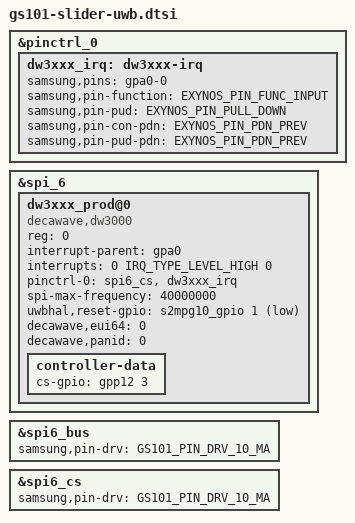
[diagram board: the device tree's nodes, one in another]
// SPDX-License-Identifier: GPL-2.0
/*
 * Google GS101 Board device tree source
 *
 * Copyright (c) 2021 Google, LLC
 *		https://www.google.com
*/

#include <dt-bindings/gpio/gpio.h>
#include <dt-bindings/pinctrl/samsung.h>

&pinctrl_0 {
	dw3xxx_irq: dw3xxx-irq {
		samsung,pins = "gpa0-0";
		samsung,pin-function = <EXYNOS_PIN_FUNC_INPUT>;
		samsung,pin-pud = <EXYNOS_PIN_PULL_DOWN>;
		samsung,pin-con-pdn = <EXYNOS_PIN_PDN_PREV>;
		samsung,pin-pud-pdn = <EXYNOS_PIN_PDN_PREV>;
	};
};

&spi_6 {
	status = "okay";
	dw3xxx_prod@0 {
		compatible = "decawave,dw3000";
		reg = <0>;

		interrupt-parent = <&gpa0>;
		interrupts = <0 IRQ_TYPE_LEVEL_HIGH 0>;

		pinctrl-names = "default";
		pinctrl-0 = <&spi6_cs &dw3xxx_irq>;

		spi-max-frequency = <40000000>;

		uwbhal,reset-gpio = <&s2mpg10_gpio 1 (GPIO_OPEN_DRAIN | GPIO_ACTIVE_LOW)>;

		decawave,eui64 = /bits/ 64 <0>;
		decawave,panid = /bits/ 16 <0>;

		status = "okay";

		controller-data {
			cs-gpio = <&gpp12 3 GPIO_ACTIVE_HIGH>;
		};
	};
};

&spi6_bus {
	samsung,pin-drv = <GS101_PIN_DRV_10_MA>;
};

&spi6_cs {
	samsung,pin-drv = <GS101_PIN_DRV_10_MA>;
};
